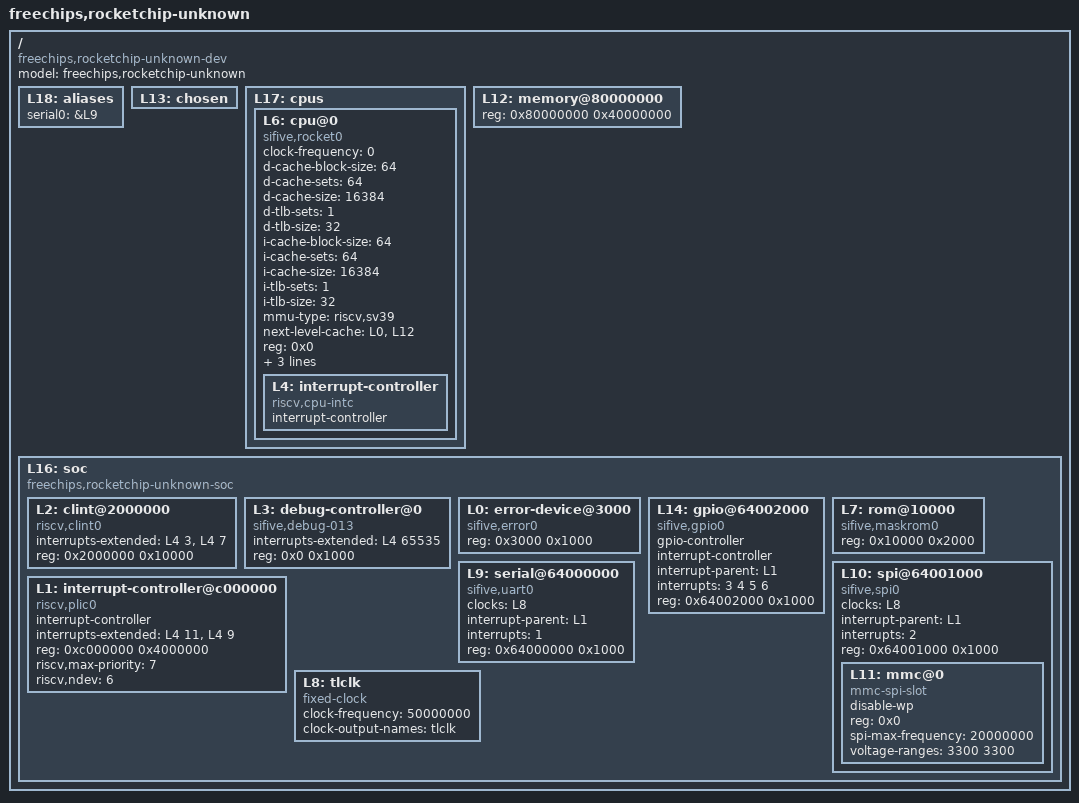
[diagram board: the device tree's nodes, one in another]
/dts-v1/;

/ {
	#address-cells = <1>;
	#size-cells = <1>;
	compatible = "freechips,rocketchip-unknown-dev";
	model = "freechips,rocketchip-unknown";
	L18: aliases {
		serial0 = &L9;
	};
	L13: chosen {
	};
	L17: cpus {
		#address-cells = <1>;
		#size-cells = <0>;
		L6: cpu@0 {
			clock-frequency = <0>;
			compatible = "sifive,rocket0", "riscv";
			d-cache-block-size = <64>;
			d-cache-sets = <64>;
			d-cache-size = <16384>;
			d-tlb-sets = <1>;
			d-tlb-size = <32>;
			device_type = "cpu";
			i-cache-block-size = <64>;
			i-cache-sets = <64>;
			i-cache-size = <16384>;
			i-tlb-sets = <1>;
			i-tlb-size = <32>;
			mmu-type = "riscv,sv39";
			next-level-cache = <&L0 &L12>;
			reg = <0x0>;
			riscv,isa = "rv64imafdc";
			status = "okay";
			timebase-frequency = <1000000>;
			tlb-split;
			L4: interrupt-controller {
				#interrupt-cells = <1>;
				compatible = "riscv,cpu-intc";
				interrupt-controller;
			};
		};
	};
	L12: memory@80000000 {
		device_type = "memory";
		reg = <0x80000000 0x40000000>;
	};
	L16: soc {
		#address-cells = <1>;
		#size-cells = <1>;
		compatible = "freechips,rocketchip-unknown-soc", "simple-bus";
		ranges;
		L2: clint@2000000 {
			compatible = "riscv,clint0";
			interrupts-extended = <&L4 3 &L4 7>;
			reg = <0x2000000 0x10000>;
			reg-names = "control";
		};
		L3: debug-controller@0 {
			compatible = "sifive,debug-013", "riscv,debug-013";
			interrupts-extended = <&L4 65535>;
			reg = <0x0 0x1000>;
			reg-names = "control";
		};
		L0: error-device@3000 {
			compatible = "sifive,error0";
			reg = <0x3000 0x1000>;
		};
		L14: gpio@64002000 {
			#gpio-cells = <2>;
			#interrupt-cells = <2>;
			compatible = "sifive,gpio0";
			gpio-controller;
			interrupt-controller;
			interrupt-parent = <&L1>;
			interrupts = <3 4 5 6>;
			reg = <0x64002000 0x1000>;
			reg-names = "control";
		};
		L1: interrupt-controller@c000000 {
			#interrupt-cells = <1>;
			compatible = "riscv,plic0";
			interrupt-controller;
			interrupts-extended = <&L4 11 &L4 9>;
			reg = <0xc000000 0x4000000>;
			reg-names = "control";
			riscv,max-priority = <7>;
			riscv,ndev = <6>;
		};
		L7: rom@10000 {
			compatible = "sifive,maskrom0";
			reg = <0x10000 0x2000>;
			reg-names = "mem";
		};
		L9: serial@64000000 {
			clocks = <&L8>;
			compatible = "sifive,uart0";
			interrupt-parent = <&L1>;
			interrupts = <1>;
			reg = <0x64000000 0x1000>;
			reg-names = "control";
		};
		L10: spi@64001000 {
			#address-cells = <1>;
			#size-cells = <0>;
			clocks = <&L8>;
			compatible = "sifive,spi0";
			interrupt-parent = <&L1>;
			interrupts = <2>;
			reg = <0x64001000 0x1000>;
			reg-names = "control";
			L11: mmc@0 {
				compatible = "mmc-spi-slot";
				disable-wp;
				reg = <0x0>;
				spi-max-frequency = <20000000>;
				voltage-ranges = <3300 3300>;
			};
		};
		L8: tlclk {
			#clock-cells = <0>;
			clock-frequency = <50000000>;
			clock-output-names = "tlclk";
			compatible = "fixed-clock";
		};
	};
};
